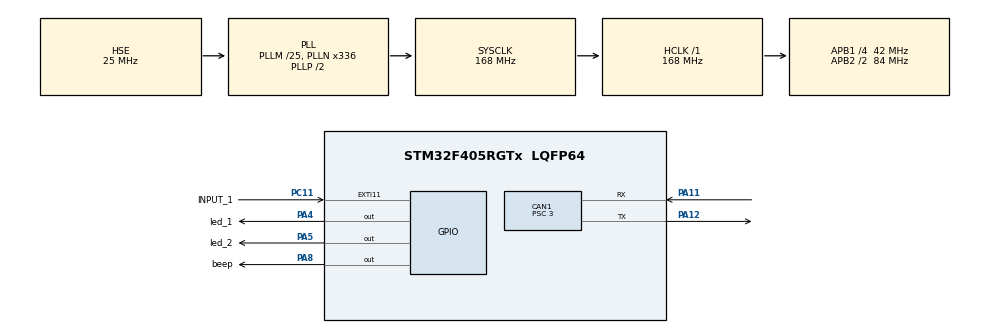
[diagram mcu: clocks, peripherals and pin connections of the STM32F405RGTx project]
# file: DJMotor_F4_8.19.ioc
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CAN1.ABOM=ENABLE
CAN1.AWUM=ENABLE
CAN1.BS1=CAN_BS1_9TQ
CAN1.BS2=CAN_BS2_4TQ
CAN1.CalculateBaudRate=1000000
CAN1.CalculateTimeBit=1000
CAN1.CalculateTimeQuantum=71.42857142857143
CAN1.NART=ENABLE
CAN1.Prescaler=3
Mcu.Family=STM32F4
Mcu.Name=STM32F405RGTx
Mcu.Package=LQFP64
NVIC.CAN1_RX0_IRQn=true\:5\:0\:true\:false\:true\:true\:true\:true
NVIC.CAN1_RX1_IRQn=true\:5\:0\:true\:false\:true\:true\:true\:true
NVIC.EXTI15_10_IRQn=true\:5\:0\:true\:false\:true\:true\:true\:true
NVIC.PriorityGroup=NVIC_PRIORITYGROUP_4
NVIC.TIM1_UP_TIM10_IRQn=true\:15\:0\:false\:false\:true\:false\:true\:true
NVIC.TIM2_IRQn=true\:5\:0\:true\:false\:true\:true\:true\:true
NVIC.TimeBase=TIM1_UP_TIM10_IRQn
NVIC.TimeBaseIP=TIM1
PA11.Mode=CAN_Activate
PA11.Signal=CAN1_RX
PA12.Mode=CAN_Activate
PA12.Signal=CAN1_TX
PA4.GPIO_Label=led_1
PA4.GPIO_PuPd=GPIO_PULLDOWN
PA4.Signal=GPIO_Output
PA5.GPIO_Label=led_2
PA5.GPIO_PuPd=GPIO_PULLDOWN
PA5.Signal=GPIO_Output
PA8.GPIO_Label=beep
PA8.GPIO_PuPd=GPIO_PULLDOWN
PA8.Signal=GPIO_Output
PC11.GPIO_Label=INPUT_1
PC11.GPIO_PuPd=GPIO_PULLDOWN
PC11.Signal=GPXTI11
PH0-OSC_IN.Mode=HSE-External-Oscillator
PH0-OSC_IN.Signal=RCC_OSC_IN
PH1-OSC_OUT.Mode=HSE-External-Oscillator
PH1-OSC_OUT.Signal=RCC_OSC_OUT
ProjectManager.HeapSize=0x200
ProjectManager.StackSize=0x400
ProjectManager.TargetToolchain=MDK-ARM V5.32
RCC.48MHZClocksFreq_Value=84000000
RCC.AHBFreq_Value=168000000
RCC.APB1CLKDivider=RCC_HCLK_DIV4
RCC.APB1Freq_Value=42000000
RCC.APB1TimFreq_Value=84000000
RCC.APB2CLKDivider=RCC_HCLK_DIV2
RCC.APB2Freq_Value=84000000
RCC.APB2TimFreq_Value=168000000
RCC.CortexFreq_Value=168000000
RCC.HCLKFreq_Value=168000000
RCC.HSE_VALUE=25000000
RCC.HSI_VALUE=16000000
RCC.LSE_VALUE=32768
RCC.PLLM=25
RCC.PLLN=336
RCC.PLLSourceVirtual=RCC_PLLSOURCE_HSE
RCC.SYSCLKFreq_VALUE=168000000
RCC.SYSCLKSource=RCC_SYSCLKSOURCE_PLLCLK
RCC.VCOOutputFreq_Value=336000000
TIM2.Period=1000-1
TIM2.Prescaler=84-1
VP_SYS_VS_tim1.Mode=TIM1
VP_TIM2_VS_ClockSourceINT.Mode=Internal
board=custom

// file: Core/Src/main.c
/* USER CODE BEGIN Header */
/**
 ******************************************************************************
 * @file           : main.c
 * @brief          : Main program body
 ******************************************************************************
 * @attention
 *
 * Copyright (c) 2026 STMicroelectronics.
 * All rights reserved.
 *
 * This software is licensed under terms that can be found in the LICENSE file
 * in the root directory of this software component.
 * If no LICENSE file comes with this software, it is provided AS-IS.
 *
 ******************************************************************************
 */
/* USER CODE END Header */
#include "main.h"
#include "can.h"
#include "tim.h"
#include "gpio.h"

/* USER CODE BEGIN Includes */
#include "pid.h"
#include "motor.h"
/* USER CODE END Includes */

void SystemClock_Config(void);

int main(void)
{

  /* MCU Configuration--------------------------------------------------------*/

  /* Reset of all peripherals, Initializes the Flash interface and the Systick. */
  HAL_Init();

  /* Configure the system clock */
  SystemClock_Config();

  /* Initialize all configured peripherals */
  MX_GPIO_Init();
  MX_CAN1_Init();
  MX_TIM2_Init();
  /* USER CODE BEGIN 2 */
  DJmotor_Init();
//  /* 1. 开启接收中断（FIFO0 有消息） */
//  HAL_CAN_ActivateNotification(&hcan1, CAN_IT_RX_FIFO0_MSG_PENDING);

//  /* 2. 开启错误中断（总线关闭、错误警告、被动错误） */
//  HAL_CAN_ActivateNotification(&hcan1, CAN_IT_BUSOFF | CAN_IT_ERROR_WARNING | CAN_IT_ERROR_PASSIVE);

//  /* 3. 启动 CAN 外设 */
//  if (HAL_CAN_Start(&hcan1) != HAL_OK)
//  {
//    Error_Handler();
//  }这些一般不写在这里

  /* USER CODE END 2 */

  /* Infinite loop */
  /* USER CODE BEGIN WHILE */
  while (1)
  {
    HAL_Delay(10);
    /* USER CODE END WHILE */

  }
}

void SystemClock_Config(void)
{
  RCC_OscInitTypeDef RCC_OscInitStruct = {0};
  RCC_ClkInitTypeDef RCC_ClkInitStruct = {0};

  /** Configure the main internal regulator output voltage
   */
  __HAL_RCC_PWR_CLK_ENABLE();
  __HAL_PWR_VOLTAGESCALING_CONFIG(PWR_REGULATOR_VOLTAGE_SCALE1);

  /** Initializes the RCC Oscillators according to the specified parameters
   * in the RCC_OscInitTypeDef structure.
   */
  RCC_OscInitStruct.OscillatorType = RCC_OSCILLATORTYPE_HSE;
  RCC_OscInitStruct.HSEState = RCC_HSE_ON;
  RCC_OscInitStruct.PLL.PLLState = RCC_PLL_ON;
  RCC_OscInitStruct.PLL.PLLSource = RCC_PLLSOURCE_HSE;
  RCC_OscInitStruct.PLL.PLLM = 25;
  RCC_OscInitStruct.PLL.PLLN = 336;
  RCC_OscInitStruct.PLL.PLLP = RCC_PLLP_DIV2;
  RCC_OscInitStruct.PLL.PLLQ = 4;
  if (HAL_RCC_OscConfig(&RCC_OscInitStruct) != HAL_OK)
  {
    Error_Handler();
  }

  /** Initializes the CPU, AHB and APB buses clocks
   */
  RCC_ClkInitStruct.ClockType = RCC_CLOCKTYPE_HCLK | RCC_CLOCKTYPE_SYSCLK | RCC_CLOCKTYPE_PCLK1 | RCC_CLOCKTYPE_PCLK2;
  RCC_ClkInitStruct.SYSCLKSource = RCC_SYSCLKSOURCE_PLLCLK;
  RCC_ClkInitStruct.AHBCLKDivider = RCC_SYSCLK_DIV1;
  RCC_ClkInitStruct.APB1CLKDivider = RCC_HCLK_DIV4;
  RCC_ClkInitStruct.APB2CLKDivider = RCC_HCLK_DIV2;

  if (HAL_RCC_ClockConfig(&RCC_ClkInitStruct, FLASH_LATENCY_5) != HAL_OK)
  {
    Error_Handler();
  }
}

/* USER CODE BEGIN 4 */
void HAL_CAN_RxFifo0MsgPendingCallback(CAN_HandleTypeDef *hcan)
{
  if (hcan->Instance == CAN1)
  {
    CAN_RxHeaderTypeDef RxHeader;
    uint8_t RxData[8];
    if (HAL_CAN_GetRxMessage(hcan, CAN_RX_FIFO0, &RxHeader, RxData) == HAL_OK)
    {
      DJMotor_Receive(RxHeader, RxData);
    }
  }
}
/* USER CODE END 4 */

void HAL_TIM_PeriodElapsedCallback(TIM_HandleTypeDef *htim)
{
  if (htim->Instance == TIM1)
  {
    HAL_IncTick();
  }
  /* USER CODE BEGIN Callback 1 */
  if (htim->Instance == TIM2)
  {
    DJMotor_Func(); // 每 1ms 调用一次
  }
  /* USER CODE END Callback 1 */
}

void Error_Handler(void)
{
  __disable_irq();
  while (1)
  {
  }
}
